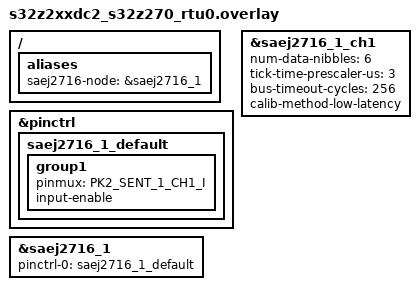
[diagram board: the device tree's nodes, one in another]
/*
 * Copyright 2025 NXP
 *
 * SPDX-License-Identifier: Apache-2.0
 */

/ {
	aliases {
		saej2716-node = &saej2716_1;
	};
};

&pinctrl {
	saej2716_1_default: saej2716_1_default {
		group1 {
			pinmux = <PK2_SENT_1_CH1_I>;
			input-enable;
		};
	};
};

&saej2716_1 {
	pinctrl-0 = <&saej2716_1_default>;
	pinctrl-names = "default";
	status = "okay";
};

&saej2716_1_ch1 {
	num-data-nibbles = <6>;
	tick-time-prescaler-us = <3>;
	bus-timeout-cycles = <256>;
	calib-method-low-latency;
	status = "okay";
};
